# R7KA8M2AD register map
Vendor: Renesas Electronics Corporation; Series: RA8; File version: 1.10.02
CPU: CM85 r0p2, little endian, MPU, FPU, VTOR, 4 interrupt priority bits, 96 interrupts
Registers are 32-bit, read-write, reset 0x0 unless marked. A register's access mark holds for its fields unless they carry their own. Offsets are from the block's base; [hi:lo] are bit positions; {n}, {i} and the like mark numbered series; 'fields as' and 'values as' point back to an identical list.

## IWDT_NS — Independent Watchdog Timer
Base 0x50202200
0x00 IWDTRR 8-bit reset 0xFF — IWDT Refresh Register
  [7:0] REFRESH
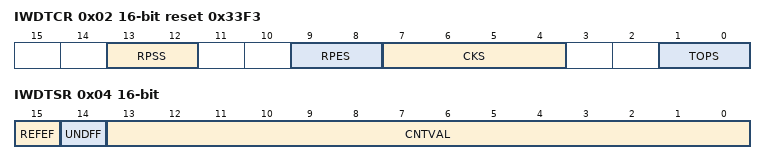
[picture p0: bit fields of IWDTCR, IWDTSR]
0x02 IWDTCR 16-bit reset 0x33F3 — IWDT Control Register
  [13:12] RPSS — Window Start Position Select
    0=25%; 1=50%; 2=75%; 3=100% (No window start position setting)
  [9:8] RPES — Window End Position Select
    0=75%; 1=50%; 2=25%; 3=0% (No window end position setting)
  [7:4] CKS — Clock Division Ratio Select
  [1:0] TOPS — Timeout Period Select
    0=128 cycles (0x007F); 1=512 cycles (0x01FF); 2=1024 cycles (0x03FF); 3=2048 cycles (0x07FF)
0x04 IWDTSR 16-bit — IWDT Status Register
  [15] REFEF — Refresh Error Flag
    0=No refresh error occurred; 1=Refresh error occurred
  [14] UNDFF — Underflow Flag
    0=No underflow occurred; 1=Underflow occurred
  [13:0] CNTVAL ro — Down-Counter Value
0x06 IWDTRCR 8-bit reset 0x80 — IWDT Reset Control Register
  [7] RSTIRQS — Reset Interrupt Request Select
    0=Enable non-maskable interrupt requests or interrupt request output; 1=Enable reset output
0x08 IWDTCSTPR 8-bit reset 0x80 — IWDT Count Stop Control Register
  [7] SLCSTP — CPU Sleep-Mode Count Stop Select
    0=Disable count stop; 1=Stop the counter when the primary CPU enters CPU Sleep mode or CPU Deep Sleep mode, and when the MCU enters Software Standby mode or Deep Software Standby mode 1

## CAC_NS — Clock Frequency Accuracy Measurement Circuit
Base 0x50202400
0x00 CACR0 8-bit — CAC Control Register 0
  [0] CFME — Clock Frequency Measurement Enable
    0=Disable; 1=Enable
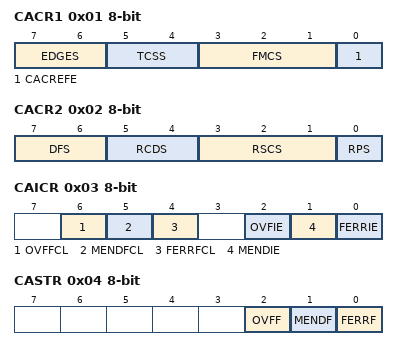
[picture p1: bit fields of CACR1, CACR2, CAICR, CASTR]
0x01 CACR1 8-bit — CAC Control Register 1
  [7:6] EDGES — Valid Edge Select
    0=Rising edge; 1=Falling edge; 2=Both rising and falling edges; 3=Setting prohibited
  [5:4] TCSS — Timer Count Clock Source Select
    0=No division; 1=x 1/4 clock; 2=x 1/8 clock; 3=x 1/32 clock
  [3:1] FMCS — Measurement Target Clock Select
    0=Main clock oscillator (CACMCLK); 1=Sub-clock oscillator (CACSCLK); 2=HOCO clock (CACHCLK); 3=MOCO clock (CACMOCLK); 4=LOCO clock (CACLCLK); 5=Peripheral module clock B (PCLKB); 6=Setting prohibited; 7=Setting prohibited
  [0] CACREFE — CACREF Pin Input Enable
    0=Disable; 1=Enable
0x02 CACR2 8-bit — CAC Control Register 2
  [7:6] DFS — Digital Filter Select
    0=Disable digital filtering; 1=Use sampling clock for the digital filter as the frequency measuring clock; 2=Use sampling clock for the digital filter as the frequency measuring clock divided by 4; 3=Use sampling clock for the digital filter as the frequency measuring clock divided by 16
  [5:4] RCDS — Measurement Reference Clock Frequency Division Ratio Select
    0=x 1/32 clock; 1=x 1/128 clock; 2=x 1/1024 clock; 3=x 1/8192 clock
  [3:1] RSCS — Measurement Reference Clock Select
    values as CACR1.FMCS
  [0] RPS — Reference Signal Select
    0=CACREF pin input; 1=Internal clock (internally generated signal)
0x03 CAICR 8-bit — CAC Interrupt Control Register
  [6] OVFFCL wo — OVFF Clear
    0=No effect; 1=The CASTR.OVFF flag is cleared
  [5] MENDFCL wo — MENDF Clear
    0=No effect; 1=The CASTR.MENDF flag is cleared
  [4] FERRFCL wo — FERRF Clear
    0=No effect; 1=The CASTR.FERRF flag is cleared
  [2] OVFIE — Overflow Interrupt Request Enable
    0=Disable; 1=Enable
  [1] MENDIE — Measurement End Interrupt Request Enable
    0=Disable; 1=Enable
  [0] FERRIE — Frequency Error Interrupt Request Enable
    0=Disable; 1=Enable
0x04 CASTR 8-bit ro — CAC Status Register
  [2] OVFF — Overflow Flag
    0=Counter has not overflowed; 1=Counter overflowed
  [1] MENDF — Measurement End Flag
    0=Measurement is in progress; 1=Measurement ended
  [0] FERRF — Frequency Error Flag
    0=Clock frequency is within the allowable range; 1=Clock frequency has deviated beyond the allowable range (frequency error)
0x06 CAULVR 16-bit — CAC Upper-Limit Value Setting Register
0x08 CALLVR 16-bit — CAC Lower-Limit Value Setting Register
0x0A CACNTBR 16-bit ro — CAC Counter Buffer Register

## POEG_NS — Port Output Enable Module for GPT
Base 0x50212000
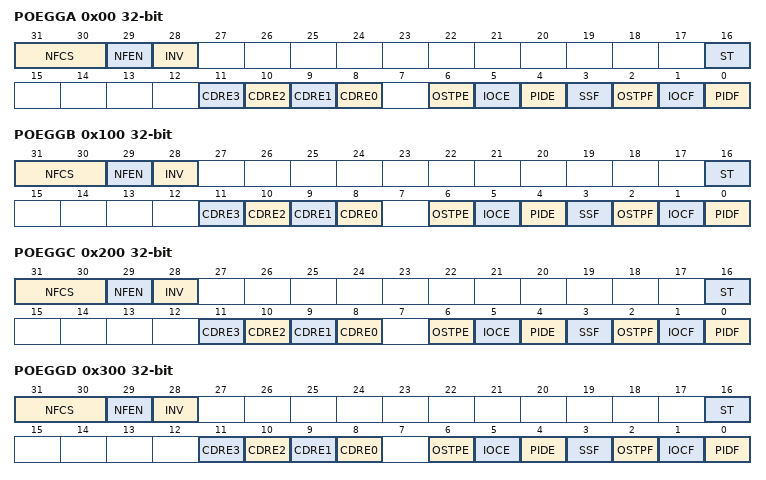
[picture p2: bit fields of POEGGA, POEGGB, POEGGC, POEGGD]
0x00 POEGGA — POEG Group A Setting Register
  [31:30] NFCS — Noise Filter Clock Select
    0=Sample GTETRGn pin input level three times every PCLKB; 1=Sample GTETRGn pin input level three times every PCLKB/8; 2=Sample GTETRGn pin input level three times every PCLKB/32; 3=Sample GTETRGn pin input level three times every PCLKB/128
  [29] NFEN — Noise Filter Enable
    0=Disable noise filtering; 1=Enable noise filtering
  [28] INV — GTETRGn Input Reverse
    0=Input GTETRGn as-is; 1=Input GTETRGn in reverse
  [16] ST ro — GTETRGn Input Status Flag
    0=GTETRGn input after filtering was 0; 1=GTETRGn input after filtering was 1
  [n+8] CDRE{n} (n=0..3)
    0=Disable output-disable request from ACMPHS{n}; 1=Enable output-disable request from ACMPHS{n}
  [6] OSTPE — Oscillation Stop Detection Enable
    0=Disable output-disable requests from oscillation stop detection; 1=Enable output-disable requests from oscillation stop detection
  [5] IOCE — Enable for GPT Output-Disable Request
    0=Disable output-disable requests from GPT; 1=Enable output-disable requests from GPT
  [4] PIDE — Port Input Detection Enable
    0=Disable output-disable requests from the GTETRGn pins; 1=Enable output-disable requests from the GTETRGn pins
  [3] SSF — Software Stop Flag
    0=No output-disable request from software occurred; 1=Output-disable request from software occurred
  [2] OSTPF — Oscillation Stop Detection Flag
    0=No output-disable request from oscillation stop detection occurred; 1=Output-disable request from oscillation stop detection occurred
  [1] IOCF — Detection Flag for GPT or ACMPHS Output-Disable Request
    0=No output-disable request from GPT or comparator interrupt occurred; 1=Output-disable request from GPT or comparator interrupt occurred
  [0] PIDF — Port Input Detection Flag
    0=No output-disable request from the GTETRGn pin occurred; 1=Output-disable request from the GTETRGn pin occurred
0x100 POEGGB — POEG Group B Setting Register
  fields as POEGGA
0x200 POEGGC — POEG Group C Setting Register
  fields as POEGGA
0x300 POEGGD — POEG Group D Setting Register
  fields as POEGGA

## CRC_NS — Cyclic Redundancy Check Calculator
Base 0x50310000
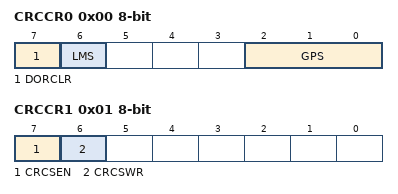
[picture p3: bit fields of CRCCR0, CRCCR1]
0x00 CRCCR0 8-bit — CRC Control Register 0
  [7] DORCLR wo — CRCDOR/CRCDOR_HA/CRCDOR_BY Register Clear
    0=No effect; 1=Clear the CRCDOR/CRCDOR_HA/CRCDOR_BY register
  [6] LMS — CRC Calculation Switching
    0=Generate CRC code for LSB-first communication; 1=Generate CRC code for MSB-first communication
  [2:0] GPS — CRC Generating Polynomial Switching
    1=8-bit CRC-8 (X8 + X2 + X + 1); 2=16-bit CRC-16 (X16 + X15 + X2 + 1); 3=16-bit CRC-CCITT (X16 + X12 + X5 + 1); 4=32-bit CRC-32 (X32 + X26 + X23 + X22 + X16 + X12 + X11 +X10 + X8 + X7 + X5 + X4 + X2 + X + 1); 5=32-bit CRC-32C (X32 + X28 + X27 + X26 + X25 + X23 + X22 + X20 + X19 + X18 + X14 + X13 + X11 + X10 + X9 + X8 + X6 + 1); other=Others (No calculation is executed)
0x01 CRCCR1 8-bit — CRC Control Register 1
  [7] CRCSEN — Snoop Enable
    0=Disabled; 1=Enabled
  [6] CRCSWR — Snoop-On-Write/Read Switch
    0=Snoop-on-read; 1=Snoop-on-write
0x04 CRCDIR — CRC Data Input Register
0x04 CRCDIR_BY 8-bit (alternate view of CRCDIR) — CRC Data Input Register
0x08 CRCDOR — CRC Data Output Register
0x08 CRCDOR_HA 16-bit (alternate view of CRCDOR) — CRC Data Output Register
0x08 CRCDOR_BY 8-bit (alternate view of CRCDOR) — CRC Data Output Register
0x0C CRCSAR 16-bit — Snoop Address Register
  [13:0] CRCSA — Register Snoop Address
